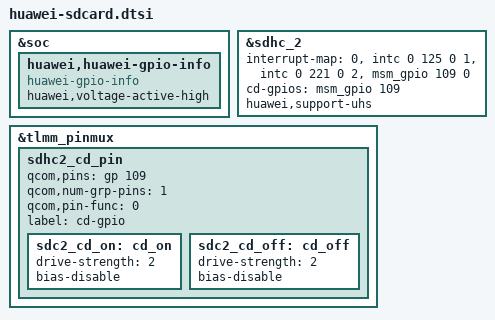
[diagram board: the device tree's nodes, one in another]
/* < DTS2014111105643 luchao 20141111 begin */
/* < DTS2015010408131 luchao 20150104 begin */
&soc {
        huawei,huawei-gpio-info {
                compatible = "huawei-gpio-info";
                huawei,voltage-active-high;
        };
     };
/* DTS2015010408131 luchao 20150104 end > */
/* DTS2014111105643 luchao 20141111 end > */
/* < DTS2014121206768 luchao 20141212 begin */
/* < DTS2015020306974 luchao 20150203 begin */
&sdhc_2 {
	interrupt-map = <0 &intc 0 125 0
		1 &intc 0 221 0
		2 &msm_gpio 109 0>;
	cd-gpios = <&msm_gpio 109 0x0>;
	/delete-property/ qcom,vdd-always-on;
	/delete-property/ qcom,vdd-io-always-on;
	huawei,support-uhs;
};
/* DTS2015020306974 luchao 20150203 end > */
/* DTS2014121206768 luchao 20141212 end > */
/* < DTS2015010408131 luchao 20150104 begin */
&tlmm_pinmux {
	sdhc2_cd_pin {
		qcom,pins = <&gp 109>;
		qcom,num-grp-pins = <1>;
		qcom,pin-func = <0>;
		label = "cd-gpio";
		sdc2_cd_on: cd_on {
			drive-strength = <2>;
			/* < DTS2015033102359 shangsai 20150331 begin */
			bias-disable;       /* NO PULL */
			/* DTS2015033102359 shangsai 20150331 end > */
		};
		sdc2_cd_off: cd_off {
			drive-strength = <2>;
			bias-disable;
		};
	};
};
/* DTS2015010408131 luchao 20150104 end > */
